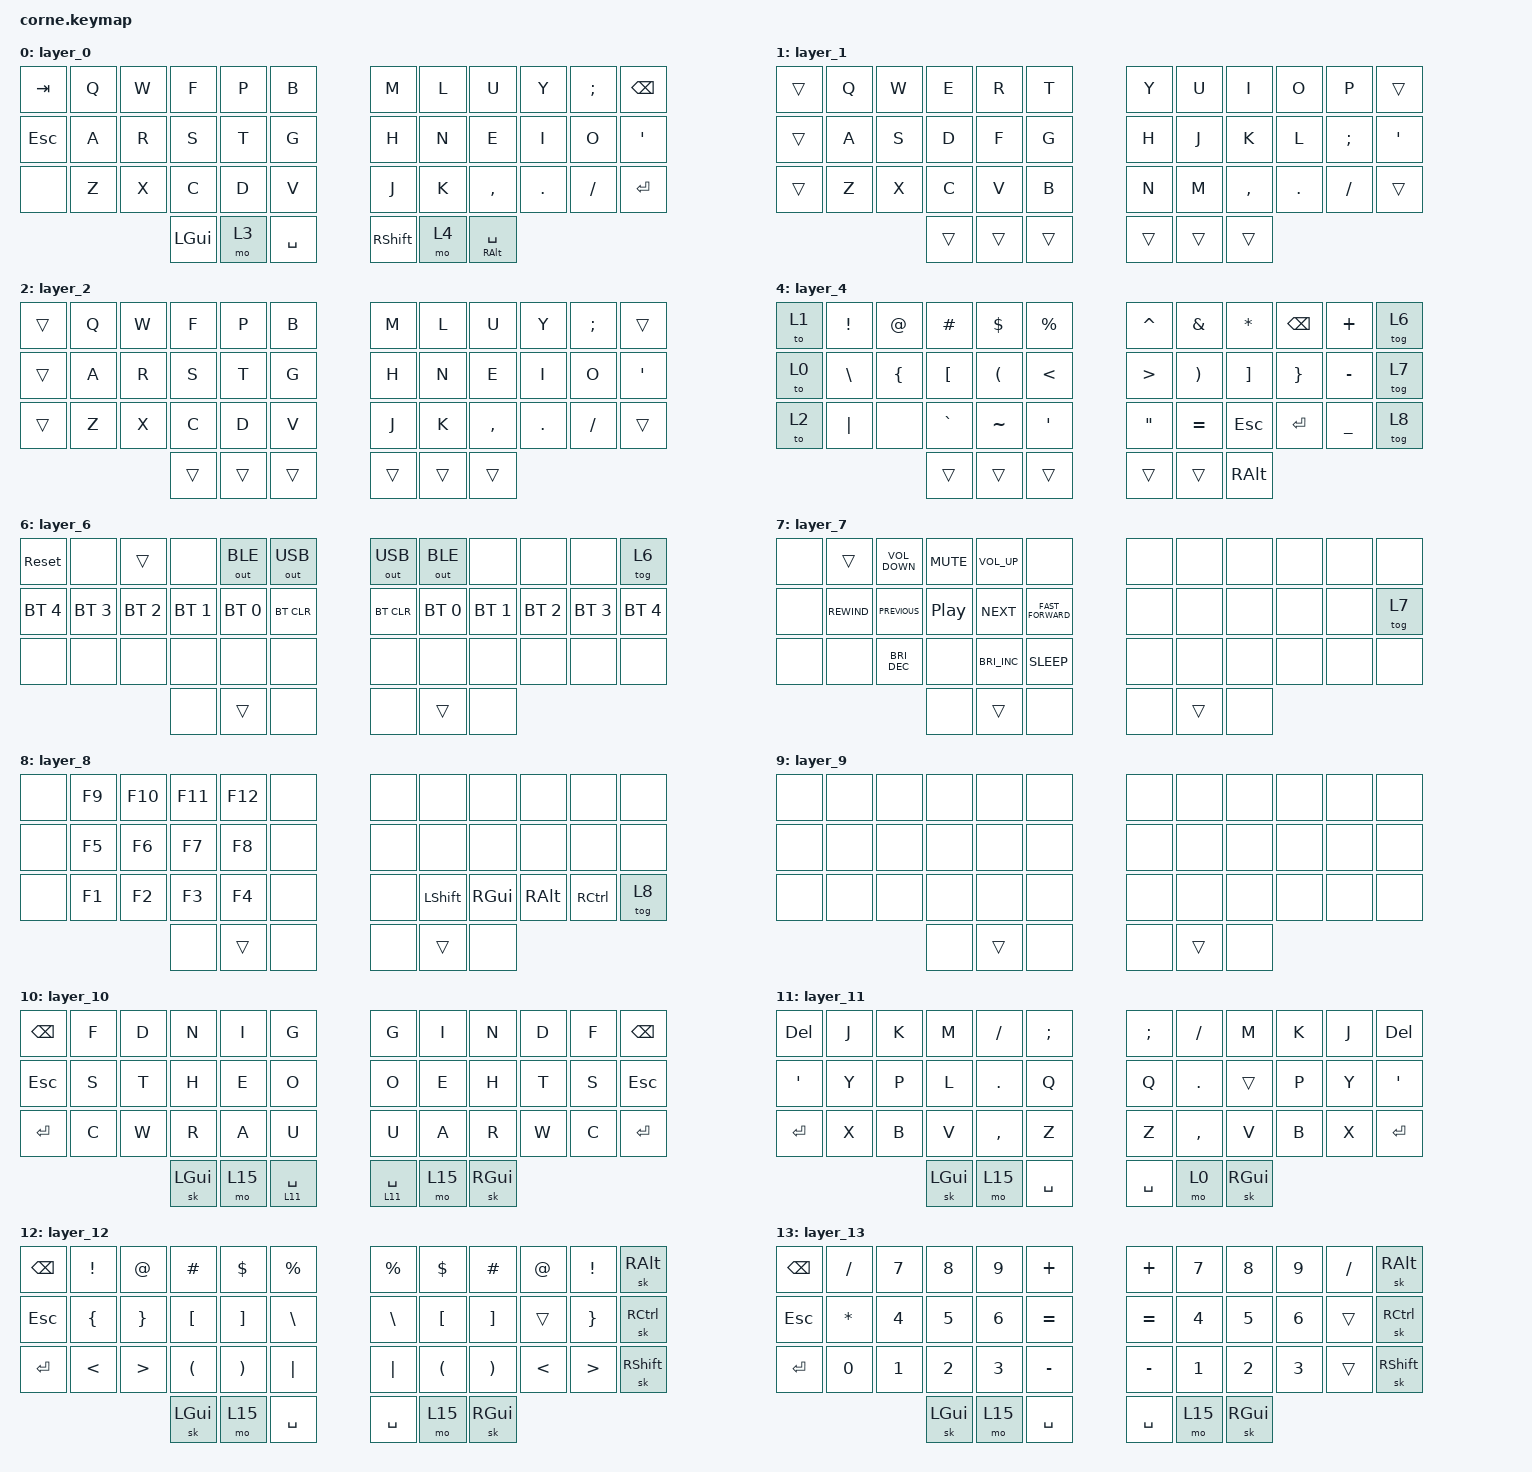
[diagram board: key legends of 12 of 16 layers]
/*
 * Copyright (c) 2020 The ZMK Contributors
 *
 * SPDX-License-Identifier: MIT
 */

#include <behaviors.dtsi>
#include <dt-bindings/zmk/keys.h>
#include <dt-bindings/zmk/bt.h>
#include <dt-bindings/zmk/outputs.h>

/ {
        behaviors {
                hm: homerow_mods {
                        compatible = "zmk,behavior-hold-tap";
                        label = "HOMEROW_MODS";
                        #binding-cells = <2>;
                        tapping-term-ms = <200>;
                        quick_tap_ms = <0>;
                        flavor = "tap-preferred";
                        bindings = <&kp>, <&kp>;
                };
        };
        combos {
                compatible = "zmk,combos";
                combo_esc {
                    timeout-ms = <60>;
                    key-positions = <40 32>;
                    bindings = <&kp ESCAPE>;
                    layers = <0 1 2 4>;
                };
                combo_enter {
                    timeout-ms = <60>;
                    key-positions = <40 33>;
                    bindings = <&kp ENTER>;
                    layers = <0 1 2 4>;
                };
                combo_tmux_left {
                    timeout-ms = <60>;
                    key-positions = <37 15 16>;
                    bindings = <&kp RC(BACKSLASH)>;
                    layers = <0 1 2 4>;
                };
                combo_tmux_right {
                    timeout-ms = <60>;
                    key-positions = <40 19 20>;
                    bindings = <&kp RC(BACKSLASH)>;
                    layers = <0 1 2 4>;
                };
                combo_alt_shift {
                    timeout-ms = <60>;
                    key-positions = <41 32>;
                    bindings = <&kp RS(RALT)>;
                    layers = <0 1 2 4>;
                };
                combo_shift_cmd {
                    timeout-ms = <60>;
                    key-positions = <39 32>;
                    bindings = <&kp RG(RSHIFT)>;
                    layers = <0 1 2 4>;
                };
                combo_left_control {
                    timeout-ms = <60>;
                    key-positions = <14 15 37>;
                    bindings = <&kp LCTRL>;
                    layers = <0 1 2 4>;
                };
                combo_right_control {
                    timeout-ms = <60>;
                    key-positions = <40 20 21>;
                    bindings = <&kp RCTRL>;
                    layers = <0 1 2 4>;
                };
                combo_control {
                    timeout-ms = <60>;
                    key-positions = <38 37>;
                    bindings = <&kp LCTRL>;
                    layers = <0 1 2 4>;
                };
                combo_tmux {
                    timeout-ms = <60>;
                    key-positions = <40 39>;
                    bindings = <&kp RC(BACKSLASH)>;
                    layers = <0 1 2 4>;
                };
                combo_hyper {
                    timeout-ms = <60>;
                    key-positions = <40 37>;
                    bindings = <&kp LG(LS(LA(LCTRL)))>;
                    layers = <0 1 2 4>;
                };
                combo_left_capslock {
                    timeout-ms = <60>;
                    key-positions = <13 14 37>;
                    bindings = <&kp CAPSLOCK>;
                    layers = <0 1 2 4>;
                };
                combo_right_capslock {
                    timeout-ms = <60>;
                    key-positions = <40 21 22>;
                    bindings = <&kp CAPSLOCK>;
                    layers = <0 1 2 4>;
                };
                combo_qwerty {
                    timeout-ms = <60>;
                    key-positions = <40 41>;
                    bindings = <&mo 1>;
                    layers = <2>;
                };
                // -- one handed combos
                combo_shift {
                    timeout-ms = <60>;
                    key-positions = <38 37>;
                    bindings = <&sk LSHIFT>;
                    layers = <10>;
                };
                combo_fj {
                    timeout-ms = <60>;
                    key-positions = <38 1>;
                    bindings = <&kp J>;
                    layers = <10>;
                };
                combo_dk {
                    timeout-ms = <60>;
                    key-positions = <38 2>;
                    bindings = <&kp K>;
                    layers = <10>;
                };
                combo_nm {
                    timeout-ms = <60>;
                    key-positions = <38 3>;
                    bindings = <&kp M>;
                    layers = <10>;
                };
                combo_iq {
                    timeout-ms = <60>;
                    key-positions = <38 4>;
                    bindings = <&kp SLASH>;
                    layers = <10>;
                };
                combo_gm {
                    timeout-ms = <60>;
                    key-positions = <38 5>;
                    bindings = <&kp SEMICOLON>;
                    layers = <10>;
                };
                combo_sy {
                    timeout-ms = <60>;
                    key-positions = <38 13>;
                    bindings = <&kp Y>;
                    layers = <10>;
                };
                combo_tp {
                    timeout-ms = <60>;
                    key-positions = <38 14>;
                    bindings = <&kp P>;
                    layers = <10>;
                };
                combo_hl {
                    timeout-ms = <60>;
                    key-positions = <38 15>;
                    bindings = <&kp L>;
                    layers = <10>;
                };
                combo_ed {
                    timeout-ms = <60>;
                    key-positions = <38 16>;
                    bindings = <&kp DOT>;
                    layers = <10>;
                };
                combo_oq {
                    timeout-ms = <60>;
                    key-positions = <38 17>;
                    bindings = <&kp Q>;
                    layers = <10>;
                };
                combo_cx {
                    timeout-ms = <60>;
                    key-positions = <38 25>;
                    bindings = <&kp X>;
                    layers = <10>;
                };
                combo_wb {
                    timeout-ms = <60>;
                    key-positions = <38 26>;
                    bindings = <&kp B>;
                    layers = <10>;
                };
                combo_rv {
                    timeout-ms = <60>;
                    key-positions = <38 27>;
                    bindings = <&kp V>;
                    layers = <10>;
                };
                combo_ac {
                    timeout-ms = <60>;
                    key-positions = <38 28>;
                    bindings = <&kp COMMA>;
                    layers = <10>;
                };
                combo_uz {
                    timeout-ms = <60>;
                    key-positions = <38 29>;
                    bindings = <&kp Z>;
                    layers = <10>;
                };
        };
        keymap {
                compatible = "zmk,keymap";
   // bluetooth layer
   // &none &none &none &none &none &none   &bt BT_CLR &bt BT_SEL 0 &bt BT_SEL 1 &bt BT_SEL 2 &bt BT_SEL 3 &bt BT_SEL 4

// ZMK JSON START
                layer_0 {
                        bindings = <
      &kp TAB &kp Q &kp W &kp F &kp P &kp B  &kp M &kp L &kp U &kp Y &kp SEMICOLON &kp BACKSPACE
   &kp ESCAPE &kp A &kp R &kp S &kp T &kp G  &kp H &kp N &kp E &kp I &kp O &kp SINGLE_QUOTE
        &none &kp Z &kp X &kp C &kp D &kp V  &kp J &kp K &kp COMMA &kp DOT &kp SLASH &kp ENTER
                   &kp LGUI &mo 3 &kp SPACE  &kp RSHIFT &mo 4 &mt RALT SPACE
                        >;
                };
                layer_1 {
                        bindings = <
   &trans &kp Q &kp W &kp E &kp R &kp T  &kp Y &kp U &kp I &kp O &kp P &trans
   &trans &kp A &kp S &kp D &kp F &kp G  &kp H &kp J &kp K &kp L &kp SEMICOLON &kp SINGLE_QUOTE
   &trans &kp Z &kp X &kp C &kp V &kp B  &kp N &kp M &kp COMMA &kp DOT &kp SLASH &trans
                   &trans &trans &trans  &trans &trans &trans
                        >;
                };
                layer_2 {
                        bindings = <
   &trans &kp Q &kp W &kp F &kp P &kp B  &kp M &kp L &kp U &kp Y &kp SEMICOLON &trans
   &trans &kp A &kp R &kp S &kp T &kp G  &kp H &kp N &kp E &kp I &kp O &kp SINGLE_QUOTE
   &trans &kp Z &kp X &kp C &kp D &kp V  &kp J &kp K &kp COMMA &kp DOT &kp SLASH &trans
                   &trans &trans &trans  &trans &trans &trans
                        >;
                };
                layer_3 {
                        bindings = <
                                &kp DELETE &tog 7 &tog 6 &kp UP &kp MINUS &to 10  &kp KP_MULTIPLY &kp N7 &kp N8 &kp N9 &kp KP_PLUS &kp BACKSPACE
                  &none &kp LALT &kp LEFT &kp DOWN &kp RIGHT &kp LS(LA(LC(F17)))  &kp KP_SLASH &kp N4 &kp N5 &kp N6 &kp KP_MINUS &kp KP_EQUAL
   &none &kp LCTRL &kp ESCAPE &kp LSHIFT &kp LS(LA(LC(F18))) &kp LS(LA(LC(F19)))  &kp SPACE &kp N1 &kp N2 &kp N3 &kp KP_DOT &kp COMMA
                                                            &trans &trans &trans  &trans &trans &kp N0
                        >;
                };
                layer_4 {
                        bindings = <
                             &to 1 &kp EXCLAMATION &kp AT &kp HASH &kp DOLLAR &kp PERCENT  &kp CARET &kp AMPERSAND &kp ASTERISK &kp BACKSPACE &kp PLUS &tog 6
   &to 0 &kp BACKSLASH &kp LEFT_BRACE &kp LEFT_BRACKET &kp LEFT_PARENTHESIS &kp LESS_THAN  &kp GREATER_THAN &kp RIGHT_PARENTHESIS &kp RIGHT_BRACKET &kp RIGHT_BRACE &kp MINUS &tog 7
                                &to 2 &kp PIPE &none &kp GRAVE &kp TILDE &kp SINGLE_QUOTE  &kp DOUBLE_QUOTES &kp EQUAL &kp ESCAPE &kp ENTER &kp UNDERSCORE &tog 8
                                                                     &trans &trans &trans  &trans &trans &kp RALT
                        >;
                };
                layer_5 {
                        bindings = <
       &to 1 &kp LS(LA(LC(Q))) &kp LG(LS(LA(LC(W)))) &kp LG(LS(LA(LC(R)))) &kp LG(LS(LA(LC(F)))) &kp LG(LS(LA(LC(M))))  &kp LG(LS(LA(LC(Y)))) &kp LG(LS(LA(LC(U)))) &kp LG(LS(LA(LC(I)))) &kp LG(LS(LA(LC(O)))) &kp LG(LS(LA(LC(SEMICOLON)))) &tog 6
   &to 0 &kp LG(LS(LA(LC(A)))) &kp LG(LS(LA(LC(S)))) &kp LG(LS(LA(LC(D)))) &kp LG(LS(LA(LC(T)))) &kp LG(LS(LA(LC(G))))  &kp LG(LS(LA(LC(H)))) &kp LG(LS(LA(LC(N)))) &kp LG(LS(LA(LC(E)))) &kp LG(LS(LA(LC(L)))) &kp LG(LS(LA(LC(P)))) &tog 7
   &to 2 &kp LG(LS(LA(LC(Z)))) &kp LG(LS(LA(LC(X)))) &kp LG(LS(LA(LC(C)))) &kp LG(LS(LA(LC(V)))) &kp LG(LS(LA(LC(B))))  &kp LG(LS(LA(LC(J)))) &kp LG(LS(LA(LC(K)))) &kp LG(LS(LA(LC(COMMA)))) &kp LG(LS(LA(LC(DOT)))) &none &tog 8
                                                                                                     &none &none &none  &none &none &none
                        >;
                };
                layer_6 {
                        bindings = <
                        &sys_reset &none &trans &none &out OUT_BLE &out OUT_USB  &out OUT_USB &out OUT_BLE &none &none &none &tog 6
    &bt BT_SEL 4 &bt BT_SEL 3 &bt BT_SEL 2 &bt BT_SEL 1 &bt BT_SEL 0 &bt BT_CLR  &bt BT_CLR &bt BT_SEL 0 &bt BT_SEL 1 &bt BT_SEL 2 &bt BT_SEL 3 &bt BT_SEL 4
                                            &none &none &none &none &none &none  &none &none &none &none &none &none
                                                             &none &trans &none  &none &trans &none
                        >;
                };
                layer_7 {
                        bindings = <
                    &none &trans &kp C_VOLUME_DOWN &kp K_MUTE &kp C_VOLUME_UP &none  &none &none &none &none &none &none
   &none &kp C_REWIND &kp C_PREVIOUS &kp C_PLAY_PAUSE &kp C_NEXT &kp C_FAST_FORWARD  &none &none &none &none &none &tog 7
            &none &none &kp C_BRIGHTNESS_DEC &none &kp C_BRIGHTNESS_INC &kp C_SLEEP  &none &none &none &none &none &none
                                                                 &none &trans &none  &none &trans &none
                        >;
                };
                layer_8 {
                        bindings = <
   &none &kp F9 &kp F10 &kp F11 &kp F12 &none  &none &none &none &none &none &none
      &none &kp F5 &kp F6 &kp F7 &kp F8 &none  &none &none &none &none &none &none
      &none &kp F1 &kp F2 &kp F3 &kp F4 &none  &none &kp LSHIFT &kp RGUI &kp RALT &kp RCTRL &tog 8
                           &none &trans &none  &none &trans &none
                        >;
                };
                layer_9 {
                        bindings = <
   &none &none &none &none &none &none  &none &none &none &none &none &none
   &none &none &none &none &none &none  &none &none &none &none &none &none
   &none &none &none &none &none &none  &none &none &none &none &none &none
                    &none &trans &none  &none &trans &none
                        >;
                };
                layer_10 {
                        bindings = <
   &kp BACKSPACE &kp F &kp D &kp N &kp I &kp G  &kp G &kp I &kp N &kp D &kp F &kp BACKSPACE
      &kp ESCAPE &kp S &kp T &kp H &kp E &kp O  &kp O &kp E &kp H &kp T &kp S &kp ESCAPE
       &kp ENTER &kp C &kp W &kp R &kp A &kp U  &kp U &kp A &kp R &kp W &kp C &kp ENTER
                  &sk LGUI &mo 15 &lt 11 SPACE  &lt 11 SPACE &mo 15 &sk RGUI
                        >;
                };
                layer_11 {
                        bindings = <
   &kp DELETE &kp J &kp K &kp M &kp SLASH &kp SEMICOLON  &kp SEMICOLON &kp SLASH &kp M &kp K &kp J &kp DELETE
       &kp SINGLE_QUOTE &kp Y &kp P &kp L &kp DOT &kp Q  &kp Q &kp DOT &trans &kp P &kp Y &kp SINGLE_QUOTE
            &kp ENTER &kp X &kp B &kp V &kp COMMA &kp Z  &kp Z &kp COMMA &kp V &kp B &kp X &kp ENTER
                              &sk LGUI &mo 15 &kp SPACE  &kp SPACE &mo 0 &sk RGUI
                        >;
                };
                layer_12 {
                        bindings = <
                           &kp BACKSPACE &kp EXCLAMATION &kp AT &kp HASH &kp DOLLAR &kp PERCENT  &kp PERCENT &kp DOLLAR &kp HASH &kp AT &kp EXCLAMATION &sk RALT
     &kp ESCAPE &kp LEFT_BRACE &kp RIGHT_BRACE &kp LEFT_BRACKET &kp RIGHT_BRACKET &kp BACKSLASH  &kp BACKSLASH &kp LEFT_BRACKET &kp RIGHT_BRACKET &trans &kp RIGHT_BRACE &sk RCTRL
   &kp ENTER &kp LESS_THAN &kp GREATER_THAN &kp LEFT_PARENTHESIS &kp RIGHT_PARENTHESIS &kp PIPE  &kp PIPE &kp LEFT_PARENTHESIS &kp RIGHT_PARENTHESIS &kp LESS_THAN &kp GREATER_THAN &sk RSHIFT
                                                                      &sk LGUI &mo 15 &kp SPACE  &kp SPACE &mo 15 &sk RGUI
                        >;
                };
                layer_13 {
                        bindings = <
    &kp BACKSPACE &kp SLASH &kp N7 &kp N8 &kp N9 &kp PLUS  &kp PLUS &kp N7 &kp N8 &kp N9 &kp SLASH &sk RALT
   &kp ESCAPE &kp ASTERISK &kp N4 &kp N5 &kp N6 &kp EQUAL  &kp EQUAL &kp N4 &kp N5 &kp N6 &trans &sk RCTRL
          &kp ENTER &kp N0 &kp N1 &kp N2 &kp N3 &kp MINUS  &kp MINUS &kp N1 &kp N2 &kp N3 &trans &sk RSHIFT
                                &sk LGUI &mo 15 &kp SPACE  &kp SPACE &mo 15 &sk RGUI
                        >;
                };
                layer_14 {
                        bindings = <
   &kp BACKSPACE &kp CARET &kp AMPERSAND &kp UP &none &none  &none &none &kp UP &kp AMPERSAND &kp CARET &sk RALT
     &kp ESCAPE &kp GRAVE &kp LEFT &kp DOWN &kp RIGHT &none  &none &kp LEFT &kp DOWN &kp RIGHT &trans &sk RCTRL
       &kp ENTER &kp TILDE &kp UNDERSCORE &none &none &none  &none &none &none &kp UNDERSCORE &kp TILDE &sk RSHIFT
                                  &sk LGUI &mo 15 &kp SPACE  &none &none &none
                        >;
                };
                layer_15 {
                        bindings = <
          &kp TAB &none &none &to 0 &none &none  &none &none &none &none &none &kp TAB
    &none &to 14 &to 12 &to 11 &to 10 &sk LCTRL  &sk RCTRL &to 10 &to 11 &to 12 &to 14 &none
   &none &to 13 &sk LALT &sk LSHIFT &none &none  &none &none &sk RSHIFT &sk RALT &to 13 &none
                             &none &trans &none  &none &trans &none
                        >;
                };
// ZMK JSON END
        };
};
